# PIC32CX1025MTSH128S1 device description
Architecture: CORTEX-M4; Family: PIC32CXMT; Series: PIC32CXMTSH
Registers are 32-bit, read-write, no defined reset value unless marked. A register's access mark holds for its fields unless they carry their own. Offsets are from the block's base; [hi:lo] are bit positions; {n}, {i} and the like mark numbered series; <NAME> marks a mode.

## MCSPI — Multi Channel Serial Peripheral Interface
Instances: MCSPI 0x48018000
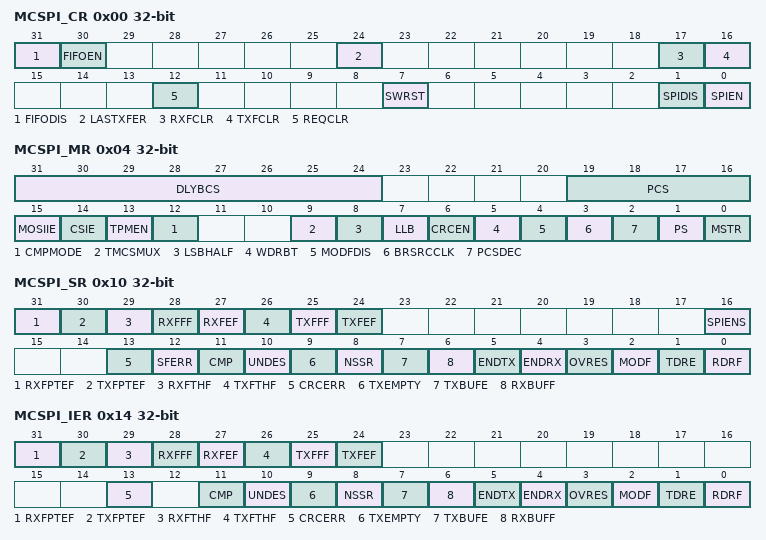
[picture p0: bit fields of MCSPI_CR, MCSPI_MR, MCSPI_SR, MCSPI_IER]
0x00 MCSPI_CR wo — Control Register
  [31] FIFODIS — FIFO Disable
  [30] FIFOEN — FIFO Enable
  [24] LASTXFER — Last Transfer
  [17] RXFCLR — Receive FIFO Clear
  [16] TXFCLR — Transmit FIFO Clear
  [12] REQCLR — Request to Clear the Comparison Trigger
  [7] SWRST — MCSPI Software Reset
  [1] SPIDIS — MCSPI Disable
  [0] SPIEN — MCSPI Enable
0x04 MCSPI_MR — Mode Register
  [31:24] DLYBCS — Delay Between Chip Selects
  [19:16] PCS — Peripheral Chip Select
  [15] MOSIIE — MOSI Inversion Enable
  [14] CSIE — Chip Select Inversion Enable
  [13] TPMEN — Two-Pin Mode Enable
  [12] CMPMODE — Comparison Mode
    0=FLAG_ONLY (Any character is received and comparison function drives CMP flag.); 1=START_CONDITION (Comparison condition must be met to start reception of all incoming characters until REQCLR is set.)
  [9] TMCSMUX — Two-pin MOSI Chip Select External Multiplexing Mode
    0=DISABLED (External MOSI lines multiplexing is not required via Chip Select lines. When MCSPI_MR.TPMEN=0, MCSPI_TWMR.MIL=1 or MCSPI_TWMR.CSM=0, TMCSMUX must be written to 0.); 1=ENABLED (Enables external multiplexing of MOSI lines via Chip Select lines. When MCSPI_MR.TPMEN=1, TMCSMUX must be written to 1 if MCSPI_TWMR.MIL=0 and MCSPI_TWMR.CSM=1.)
  [8] LSBHALF — LSB Timing Selection
  [7] LLB — Local Loopback Enable
  [6] CRCEN — CRC Enable
  [5] WDRBT — Wait for Data Read Before Transfer
  [4] MODFDIS — Mode Fault Detection
  [3] BRSRCCLK — Bit Rate Source Clock
    0=PERIPH_CLK (The peripheral clock is the source clock for the bit rate generation.); 1=GCLK (PMC GCLK is the source clock for the bit rate generation, thus the bit rate can be independent of the core/peripheral clock.)
  [2] PCSDEC — Chip Select Decode
  [1] PS — Peripheral Select
  [0] MSTR — Host/Client Mode
0x08 MCSPI_RDR ro — Receive Data Register
  [19:16] PCS <DEFAULT> — Peripheral Chip Select
  [15:0] RD <DEFAULT> — Receive Data
  [31:16] RD1 <FIFO_MULTI_DATA_16> — Receive Data
  [15:0] RD0 <FIFO_MULTI_DATA_16> — Receive Data
  [31:24] RD3 <FIFO_MULTI_DATA_8> — Receive Data
  [23:16] RD2 <FIFO_MULTI_DATA_8> — Receive Data
  [15:8] RD1 <FIFO_MULTI_DATA_8> — Receive Data
  [7:0] RD0 <FIFO_MULTI_DATA_8> — Receive Data
0x0C MCSPI_TDR wo — Transmit Data Register
  [24] LASTXFER <DEFAULT> — Last Transfer
  [19:16] PCS <DEFAULT> — Peripheral Chip Select
  [15:0] TD <DEFAULT> — Transmit Data
  [31:16] TD1 <FIFO_MULTI_DATA> — Transmit Data
  [15:0] TD0 <FIFO_MULTI_DATA> — Transmit Data
0x10 MCSPI_SR ro — Status Register
  [31] RXFPTEF — Receive FIFO Pointer Error Flag
  [30] TXFPTEF — Transmit FIFO Pointer Error Flag
  [29] RXFTHF — Receive FIFO Threshold Flag
  [28] RXFFF — Receive FIFO Full Flag
  [27] RXFEF — Receive FIFO Empty Flag
  [26] TXFTHF — Transmit FIFO Threshold Flag (cleared on read)
  [25] TXFFF — Transmit FIFO Full Flag (cleared on read)
  [24] TXFEF — Transmit FIFO Empty Flag (cleared on read)
  [16] SPIENS — MCSPI Enable Status
  [13] CRCERR — CRC Error (cleared on read)
  [12] SFERR — Client Frame Error (cleared on read)
  [11] CMP — Comparison Status (cleared on read)
  [10] UNDES — Underrun Error Status (Client mode only) (cleared on read)
  [9] TXEMPTY — Transmission Registers Empty (cleared by writing MCSPI_TDR)
  [8] NSSR — NSS Rising (cleared on read)
  [7] TXBUFE — TX Buffer Empty (cleared by writing MCSPI_TCR or MCSPI_TNCR)
  [6] RXBUFF — RX Buffer Full (cleared by writing MCSPI_RCR or MCSPI_RNCR)
  [5] ENDTX — End of TX Buffer (cleared by writing MCSPI_TCR or MCSPI_TNCR)
  [4] ENDRX — End of RX Buffer (cleared by writing MCSPI_RCR or MCSPI_RNCR)
  [3] OVRES — Overrun Error Status (cleared on read)
  [2] MODF — Mode Fault Error (cleared on read)
  [1] TDRE — Transmit Data Register Empty (cleared by writing MCSPI_TDR)
  [0] RDRF — Receive Data Register Full (cleared by reading MCSPI_RDR)
0x14 MCSPI_IER wo — Interrupt Enable Register
  [31] RXFPTEF — RXFPTEF Interrupt Enable
  [30] TXFPTEF — TXFPTEF Interrupt Enable
  [29] RXFTHF — RXFTHF Interrupt Enable
  [28] RXFFF — RXFFF Interrupt Enable
  [27] RXFEF — RXFEF Interrupt Enable
  [26] TXFTHF — TXFTHF Interrupt Enable
  [25] TXFFF — TXFFF Interrupt Enable
  [24] TXFEF — TXFEF Interrupt Enable
  [13] CRCERR — CRC Error Interrupt Enable
  [11] CMP — Comparison Interrupt Enable
  [10] UNDES — Underrun Error Interrupt Enable
  [9] TXEMPTY — Transmission Registers Empty Enable
  [8] NSSR — NSS Rising Interrupt Enable
  [7] TXBUFE — Transmit Buffer Empty Interrupt Enable
  [6] RXBUFF — Receive Buffer Full Interrupt Enable
  [5] ENDTX — End of Transmit Buffer Interrupt Enable
  [4] ENDRX — End of Receive Buffer Interrupt Enable
  [3] OVRES — Overrun Error Interrupt Enable
  [2] MODF — Mode Fault Error Interrupt Enable
  [1] TDRE — MCSPI Transmit Data Register Empty Interrupt Enable
  [0] RDRF — Receive Data Register Full Interrupt Enable
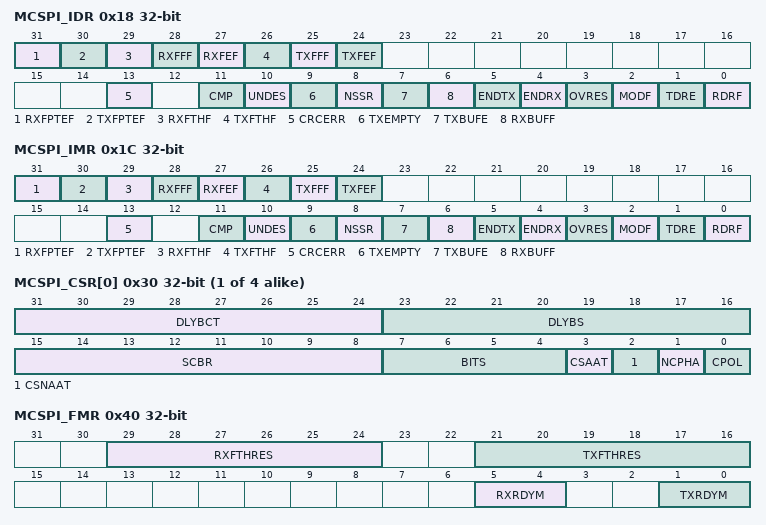
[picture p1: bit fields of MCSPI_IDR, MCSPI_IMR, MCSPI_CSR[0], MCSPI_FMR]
0x18 MCSPI_IDR wo — Interrupt Disable Register
  [31] RXFPTEF — RXFPTEF Interrupt Disable
  [30] TXFPTEF — TXFPTEF Interrupt Disable
  [29] RXFTHF — RXFTHF Interrupt Disable
  [28] RXFFF — RXFFF Interrupt Disable
  [27] RXFEF — RXFEF Interrupt Disable
  [26] TXFTHF — TXFTHF Interrupt Disable
  [25] TXFFF — TXFFF Interrupt Disable
  [24] TXFEF — TXFEF Interrupt Disable
  [13] CRCERR — CRC Error Interrupt Disable
  [11] CMP — Comparison Interrupt Disable
  [10] UNDES — Underrun Error Interrupt Disable
  [9] TXEMPTY — Transmission Registers Empty Disable
  [8] NSSR — NSS Rising Interrupt Disable
  [7] TXBUFE — Transmit Buffer Empty Interrupt Disable
  [6] RXBUFF — Receive Buffer Full Interrupt Disable
  [5] ENDTX — End of Transmit Buffer Interrupt Disable
  [4] ENDRX — End of Receive Buffer Interrupt Disable
  [3] OVRES — Overrun Error Interrupt Disable
  [2] MODF — Mode Fault Error Interrupt Disable
  [1] TDRE — MCSPI Transmit Data Register Empty Interrupt Disable
  [0] RDRF — Receive Data Register Full Interrupt Disable
0x1C MCSPI_IMR ro — Interrupt Mask Register
  [31] RXFPTEF — RXFPTEF Interrupt Mask
  [30] TXFPTEF — TXFPTEF Interrupt Mask
  [29] RXFTHF — RXFTHF Interrupt Mask
  [28] RXFFF — RXFFF Interrupt Mask
  [27] RXFEF — RXFEF Interrupt Mask
  [26] TXFTHF — TXFTHF Interrupt Mask
  [25] TXFFF — TXFFF Interrupt Mask
  [24] TXFEF — TXFEF Interrupt Mask
  [13] CRCERR — CRC Error Interrupt Mask
  [11] CMP — Comparison Interrupt Mask
  [10] UNDES — Underrun Error Interrupt Mask
  [9] TXEMPTY — Transmission Registers Empty Mask
  [8] NSSR — NSS Rising Interrupt Mask
  [7] TXBUFE — Transmit Buffer Empty Interrupt Mask
  [6] RXBUFF — Receive Buffer Full Interrupt Mask
  [5] ENDTX — End of Transmit Buffer Interrupt Mask
  [4] ENDRX — End of Receive Buffer Interrupt Mask
  [3] OVRES — Overrun Error Interrupt Mask
  [2] MODF — Mode Fault Error Interrupt Mask
  [1] TDRE — MCSPI Transmit Data Register Empty Interrupt Mask
  [0] RDRF — Receive Data Register Full Interrupt Mask
{0x30+4i} MCSPI_CSR[{i}] (i=0..3) — Chip Select Register (CS_number = 0)
  [31:24] DLYBCT — Delay Between Consecutive Transfers
  [23:16] DLYBS — Delay Before SPCK
  [15:8] SCBR — Serial Clock Bit Rate
  [7:4] BITS — Bits Per Transfer
    {v}=_{v+8}_BIT ({v+8} bits for transfer) (v=0..8)
  [3] CSAAT — Chip Select Active After Transfer
  [2] CSNAAT — Chip Select Not Active After Transfer (ignored if CSAAT = 1)
  [1] NCPHA — Clock Phase
  [0] CPOL — Clock Polarity
0x40 MCSPI_FMR — FIFO Mode Register
  [29:24] RXFTHRES — Receive FIFO Threshold
  [21:16] TXFTHRES — Transmit FIFO Threshold
  [5:4] RXRDYM — Receive Data Register Full Mode
    0=ONE_DATA (RDRF will be at level '1' when at least one unread data is in the Receive FIFO.); 1=TWO_DATA (RDRF will be at level '1' when at least two unread data are in the Receive FIFO. Cannot be used when MCSPI_MR.MSTR =1, or if MCSPI_MR.PS =1.); 2=FOUR_DATA (RDRF will be at level '1' when at least four unread data are in the Receive FIFO. Cannot be used when MCSPI_CSRx.BITS is greater than 0, or if MCSPI_MR.MSTR = 1, or if MCSPI_MR.PS = 1.)
  [1:0] TXRDYM — Transmit Data Register Empty Mode
    0=ONE_DATA (TDRE will be at level '1' when at least one data can be written in the Transmit FIFO.); 1=TWO_DATA (TDRE will be at level '1' when at least two data can be written in the Transmit FIFO. Cannot be used if MCSPI_MR.PS =1.)
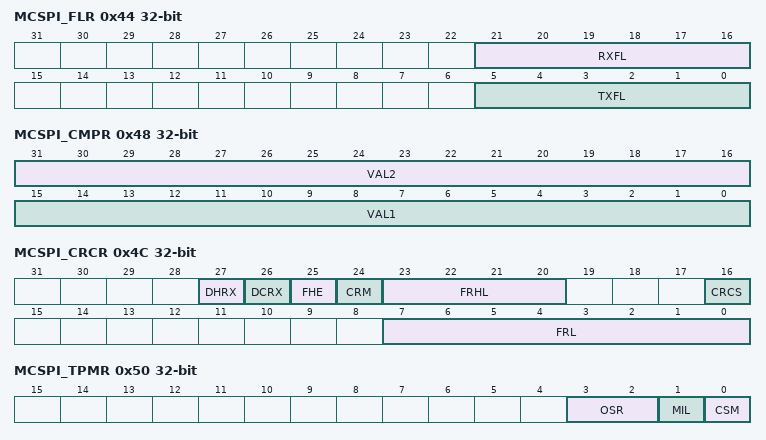
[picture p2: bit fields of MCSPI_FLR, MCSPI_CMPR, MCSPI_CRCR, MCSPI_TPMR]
0x44 MCSPI_FLR ro — FIFO Level Register
  [21:16] RXFL — Receive FIFO Level
  [5:0] TXFL — Transmit FIFO Level
0x48 MCSPI_CMPR — Comparison Register
  [31:16] VAL2 — Second Comparison Value for Received Character
  [15:0] VAL1 — First Comparison Value for Received Character
0x4C MCSPI_CRCR — CRC Register
  [27] DHRX — Disable Header Receiving
  [26] DCRX — Disable CRC Receiving
  [25] FHE — Frame Header Excluded
  [24] CRM — Continuous Read Mode
  [23:20] FRHL — Frame Header Length
  [16] CRCS — CRC Size
    0=_16B_CRC (CRC size is 16 bits.); 1=_32B_CRC (CRC size is 32 bits.)
  [7:0] FRL — Frame Length
0x50 MCSPI_TPMR — Two-Pin Mode Register
  [3:2] OSR — OverSampling Rate
  [1] MIL — Multiple Input Lines
  [0] CSM — Chip Select Mode
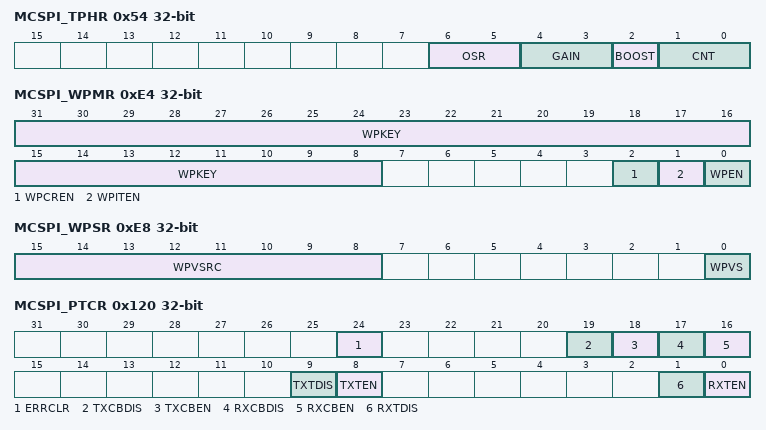
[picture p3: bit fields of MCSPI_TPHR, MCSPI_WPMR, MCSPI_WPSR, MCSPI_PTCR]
0x54 MCSPI_TPHR ro — Two-Pin Header Register
  [6:5] OSR — OverSampling Rate
  [4:3] GAIN
  [2] BOOST — Current Boost
  [1:0] CNT — Frame Counter
0xE4 MCSPI_WPMR — Write Protection Mode Register
  [31:8] WPKEY — Write Protection Key
    0x535049=PASSWD (Writing any other value in this field aborts the write operation of WPEN. Always reads as 0.)
  [2] WPCREN — Write Protection Control Register Enable
  [1] WPITEN — Write Protection Interrupt Enable
  [0] WPEN — Write Protection Enable
0xE8 MCSPI_WPSR ro — Write Protection Status Register
  [15:8] WPVSRC — Write Protection Violation Source
  [0] WPVS — Write Protection Violation Status
0x100 MCSPI_RPR — Receive Pointer Register
  [31:0] RXPTR
0x104 MCSPI_RCR — Receive Counter Register
  [15:0] RXCTR
0x108 MCSPI_TPR — Transmit Pointer Register
  [31:0] TXPTR — Transmit Counter Register
0x10C MCSPI_TCR — Transmit Counter Register
  [15:0] TXCTR
0x110 MCSPI_RNPR — Receive Next Pointer Register
  [31:0] RXNPTR — Receive Next Pointer
0x114 MCSPI_RNCR — Receive Next Counter Register
  [15:0] RXNCTR — Receive Next Counter
0x118 MCSPI_TNPR — Transmit Next Pointer Register
  [31:0] TXNPTR — Transmit Next Pointer
0x11C MCSPI_TNCR — Transmit Next Counter Register
  [15:0] TXNCTR — Transmit Counter Next
0x120 MCSPI_PTCR wo — Transfer Control Register
  [24] ERRCLR — Transfer Bus Error Clear
  [19] TXCBDIS — Transmitter Circular Buffer Disable
  [18] TXCBEN — Transmitter Circular Buffer Enable
  [17] RXCBDIS — Receiver Circular Buffer Disable
  [16] RXCBEN — Receiver Circular Buffer Enable
  [9] TXTDIS — Transmitter Transfer Disable
  [8] TXTEN — Transmitter Transfer Enable
  [1] RXTDIS — Receiver Transfer Disable
  [0] RXTEN — Receiver Transfer Enable
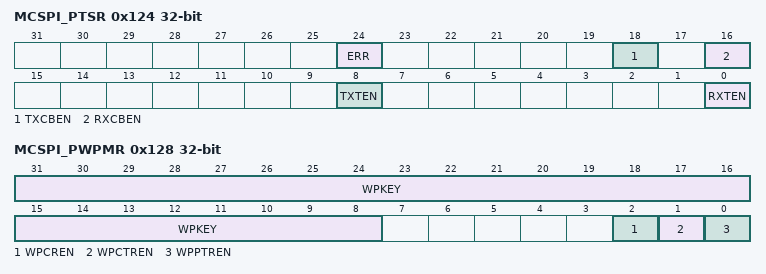
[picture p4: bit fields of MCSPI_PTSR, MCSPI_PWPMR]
0x124 MCSPI_PTSR ro — Transfer Status Register
  [24] ERR — Transfer Bus Error
  [18] TXCBEN — Transmitter Circular Buffer Enable
  [16] RXCBEN — Receiver Circular Buffer Enable
  [8] TXTEN — Transmitter Transfer Enable
  [0] RXTEN — Receiver Transfer Enable
0x128 MCSPI_PWPMR — Write Protection Mode Register
  [31:8] WPKEY — Write Protection Key
    0x504443=PASSWD (Writing any other value in this field aborts the write operation. Always reads as 0.)
  [2] WPCREN — Write Protection Control Register Enable
  [1] WPCTREN — Write Protection Counter Registers Enable
  [0] WPPTREN — Write Protection Pointer Registers Enable

## MEM2MEM — Memory to Memory
Instances: MEM2MEM0 0x40034000, MEM2MEM1 0x48004000
Registers as MCSPI (with MCSPI read as MEM2MEM), without MCSPI_CR, MCSPI_RDR, MCSPI_TDR, MCSPI_SR, MCSPI_IER, MCSPI_IDR, MCSPI_IMR, MCSPI_CSR, MCSPI_FMR, MCSPI_FLR, MCSPI_CMPR, MCSPI_CRCR, MCSPI_TPMR, MCSPI_TPHR, MCSPI_WPMR, MCSPI_WPSR; these are added or differ:
0x00 MEM2MEM_THR — Transfer Holding Register
  [31:0] THDATA — Transfer Holding Data
0x04 MEM2MEM_MR — Mode Register
  [1:0] TSIZE — Transfer Size
    0=T_8BIT (The buffer size is defined in bytes.); 1=T_16BIT (The buffer size is defined in half-words (16-bit).); 2=T_32BIT (The buffer size is defined in words (32-bit). Default value.)
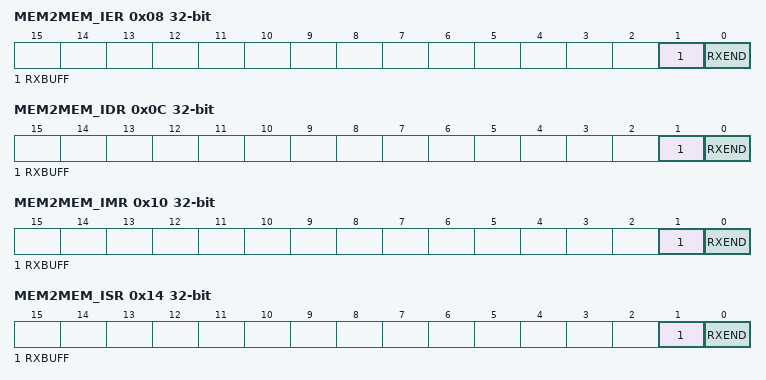
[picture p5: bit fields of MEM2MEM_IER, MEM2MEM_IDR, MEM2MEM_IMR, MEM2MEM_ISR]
0x08 MEM2MEM_IER wo — Interrupt Enable Register
  [1] RXBUFF — Buffer Full Interrupt Enable
  [0] RXEND — End of Transfer Interrupt Enable
0x0C MEM2MEM_IDR wo — Interrupt Disable Register
  [1] RXBUFF — Buffer Full Interrupt Disable
  [0] RXEND — End of Transfer Interrupt Disable
0x10 MEM2MEM_IMR ro — Interrupt Mask Register
  [1] RXBUFF — Buffer Full Interrupt Mask
  [0] RXEND — End of Transfer Interrupt Mask
0x14 MEM2MEM_ISR ro — Interrupt Status Register
  [1] RXBUFF — Buffer Full
  [0] RXEND — End of Transfer
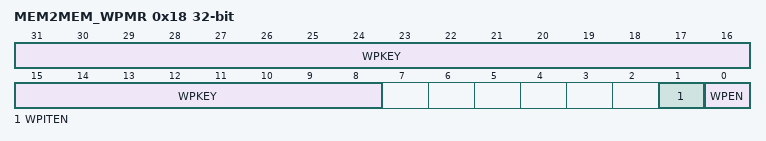
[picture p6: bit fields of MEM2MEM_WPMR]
0x18 MEM2MEM_WPMR — Write Protection Mode Register
  [31:8] WPKEY — Write Protection Key
    0x4D454D=PASSWD (Writing any other value in this field aborts the write operation of the WPEN, WPITEN bits. Always reads as 0.)
  [1] WPITEN — Write Protection Interruption Enable
  [0] WPEN — Write Protection Configuration Enable

## Notices in the file
Copyright %copyright_year% Microchip Technology Inc.
SPDX-License-Identifier: Apache-2.0
Licensed under the Apache License, Version 2.0 (the "License");
you may not use this file except in compliance with the License.
You may obtain a copy of the License at
http://www.apache.org/licenses/LICENSE-2.0
Unless required by applicable law or agreed to in writing, software
distributed under the License is distributed on an "AS IS" BASIS,
WITHOUT WARRANTIES OR CONDITIONS OF ANY KIND, either express or implied.
See the License for the specific language governing permissions and
limitations under the License.
